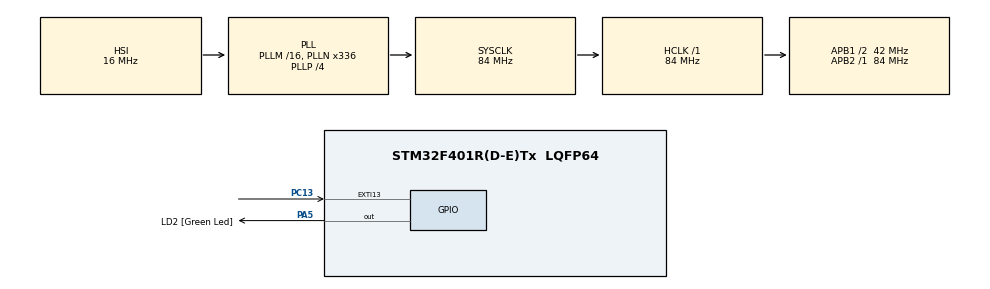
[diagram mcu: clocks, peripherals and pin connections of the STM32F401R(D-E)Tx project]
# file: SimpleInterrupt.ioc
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Mcu.Family=STM32F4
Mcu.Name=STM32F401R(D-E)Tx
Mcu.Package=LQFP64
NVIC.EXTI15_10_IRQn=true\:0\:1\:false\:false\:true
NVIC.PriorityGroup=NVIC_PRIORITYGROUP_0
PA13.GPIO_Label=TMS
PA13.Signal=SYS_JTMS-SWDIO
PA14.GPIO_Label=TCK
PA14.Signal=SYS_JTCK-SWCLK
PA2.GPIO_Label=USART_TX
PA2.GPIO_Mode=GPIO_MODE_AF_PP
PA2.GPIO_PuPd=GPIO_NOPULL
PA2.GPIO_Speed=GPIO_SPEED_FREQ_LOW
PA2.Signal=USART2_TX
PA3.GPIO_Label=USART_RX
PA3.GPIO_Mode=GPIO_MODE_AF_PP
PA3.GPIO_PuPd=GPIO_NOPULL
PA3.GPIO_Speed=GPIO_SPEED_FREQ_LOW
PA3.Signal=USART2_RX
PA5.GPIO_Label=LD2 [Green Led]
PA5.GPIO_Mode=GPIO_MODE_OUTPUT_PP
PA5.GPIO_PuPd=GPIO_NOPULL
PA5.GPIO_Speed=GPIO_SPEED_FREQ_LOW
PA5.Signal=GPIO_Output
PB3.GPIO_Label=SWO
PB3.Signal=SYS_JTDO-SWO
PC13-ANTI_TAMP.GPIO_ModeDefaultEXTI=GPIO_MODE_IT_FALLING
PC13-ANTI_TAMP.Signal=GPXTI13
PC14-OSC32_IN.Signal=RCC_OSC32_IN
PC15-OSC32_OUT.Signal=RCC_OSC32_OUT
PH0\ -\ OSC_IN.Signal=RCC_OSC_IN
PH1\ -\ OSC_OUT.Signal=RCC_OSC_OUT
ProjectManager.HeapSize=0x200
ProjectManager.StackSize=0x400
ProjectManager.TargetToolchain=SW4STM32
RCC.AHBFreq_Value=84000000
RCC.APB1CLKDivider=RCC_HCLK_DIV2
RCC.APB1Freq_Value=42000000
RCC.APB1TimFreq_Value=84000000
RCC.APB2Freq_Value=84000000
RCC.APB2TimFreq_Value=84000000
RCC.CortexFreq_Value=84000000
RCC.HCLKFreq_Value=84000000
RCC.HSE_VALUE=8000000
RCC.HSI_VALUE=16000000
RCC.LSE_VALUE=32768
RCC.PLLN=336
RCC.PLLP=RCC_PLLP_DIV4
RCC.PLLQ=7
RCC.SYSCLKFreq_VALUE=84000000
RCC.SYSCLKSource=RCC_SYSCLKSOURCE_PLLCLK
RCC.VCOOutputFreq_Value=336000000
board=NUCLEO-F401RE

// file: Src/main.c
/**
  ******************************************************************************
  * File Name          : main.c
  * Description        : Main program body
  ******************************************************************************
  *
  * COPYRIGHT(c) 2017 STMicroelectronics
  *
  * Redistribution and use in source and binary forms, with or without modification,
  * are permitted provided that the following conditions are met:
  *   1. Redistributions of source code must retain the above copyright notice,
  *      this list of conditions and the following disclaimer.
  *   2. Redistributions in binary form must reproduce the above copyright notice,
  *      this list of conditions and the following disclaimer in the documentation
  *      and/or other materials provided with the distribution.
  *   3. Neither the name of STMicroelectronics nor the names of its contributors
  *      may be used to endorse or promote products derived from this software
  *      without specific prior written permission.
  *
  * THIS SOFTWARE IS PROVIDED BY THE COPYRIGHT HOLDERS AND CONTRIBUTORS "AS IS"
  * AND ANY EXPRESS OR IMPLIED WARRANTIES, INCLUDING, BUT NOT LIMITED TO, THE
  * IMPLIED WARRANTIES OF MERCHANTABILITY AND FITNESS FOR A PARTICULAR PURPOSE ARE
  * DISCLAIMED. IN NO EVENT SHALL THE COPYRIGHT HOLDER OR CONTRIBUTORS BE LIABLE
  * FOR ANY DIRECT, INDIRECT, INCIDENTAL, SPECIAL, EXEMPLARY, OR CONSEQUENTIAL
  * DAMAGES (INCLUDING, BUT NOT LIMITED TO, PROCUREMENT OF SUBSTITUTE GOODS OR
  * SERVICES; LOSS OF USE, DATA, OR PROFITS; OR BUSINESS INTERRUPTION) HOWEVER
  * CAUSED AND ON ANY THEORY OF LIABILITY, WHETHER IN CONTRACT, STRICT LIABILITY,
  * OR TORT (INCLUDING NEGLIGENCE OR OTHERWISE) ARISING IN ANY WAY OUT OF THE USE
  * OF THIS SOFTWARE, EVEN IF ADVISED OF THE POSSIBILITY OF SUCH DAMAGE.
  *
  ******************************************************************************
  */
#include "main.h"
#include "stm32f4xx_hal.h"
#include "gpio.h"

/* USER CODE BEGIN PV */
/* Private variables ---------------------------------------------------------*/

/* USER CODE END PV */

void SystemClock_Config(void);
void Error_Handler(void);

/* USER CODE BEGIN PFP */
/* Private function prototypes -----------------------------------------------*/

/* USER CODE END PFP */

int main(void)
{

  /* MCU Configuration----------------------------------------------------------*/

  /* Reset of all peripherals, Initializes the Flash interface and the Systick. */
  HAL_Init();

  /* Configure the system clock */
  SystemClock_Config();

  /* Initialize all configured peripherals */
  MX_GPIO_Init();

  /* Infinite loop */
  while (1)
  {

  }

}

/** System Clock Configuration
*/
void SystemClock_Config(void)
{

  RCC_OscInitTypeDef RCC_OscInitStruct;
  RCC_ClkInitTypeDef RCC_ClkInitStruct;

    /**Configure the main internal regulator output voltage
    */
  __HAL_RCC_PWR_CLK_ENABLE();

  __HAL_PWR_VOLTAGESCALING_CONFIG(PWR_REGULATOR_VOLTAGE_SCALE2);

    /**Initializes the CPU, AHB and APB busses clocks
    */
  RCC_OscInitStruct.OscillatorType = RCC_OSCILLATORTYPE_HSI;
  RCC_OscInitStruct.HSIState = RCC_HSI_ON;
  RCC_OscInitStruct.HSICalibrationValue = 16;
  RCC_OscInitStruct.PLL.PLLState = RCC_PLL_ON;
  RCC_OscInitStruct.PLL.PLLSource = RCC_PLLSOURCE_HSI;
  RCC_OscInitStruct.PLL.PLLM = 16;
  RCC_OscInitStruct.PLL.PLLN = 336;
  RCC_OscInitStruct.PLL.PLLP = RCC_PLLP_DIV4;
  RCC_OscInitStruct.PLL.PLLQ = 7;
  if (HAL_RCC_OscConfig(&RCC_OscInitStruct) != HAL_OK)
  {
    Error_Handler();
  }

    /**Initializes the CPU, AHB and APB busses clocks
    */
  RCC_ClkInitStruct.ClockType = RCC_CLOCKTYPE_HCLK|RCC_CLOCKTYPE_SYSCLK
                              |RCC_CLOCKTYPE_PCLK1|RCC_CLOCKTYPE_PCLK2;
  RCC_ClkInitStruct.SYSCLKSource = RCC_SYSCLKSOURCE_PLLCLK;
  RCC_ClkInitStruct.AHBCLKDivider = RCC_SYSCLK_DIV1;
  RCC_ClkInitStruct.APB1CLKDivider = RCC_HCLK_DIV2;
  RCC_ClkInitStruct.APB2CLKDivider = RCC_HCLK_DIV1;

  if (HAL_RCC_ClockConfig(&RCC_ClkInitStruct, FLASH_LATENCY_2) != HAL_OK)
  {
    Error_Handler();
  }

    /**Configure the Systick interrupt time
    */
  HAL_SYSTICK_Config(HAL_RCC_GetHCLKFreq()/1000);

    /**Configure the Systick
    */
  HAL_SYSTICK_CLKSourceConfig(SYSTICK_CLKSOURCE_HCLK);

  /* SysTick_IRQn interrupt configuration */
  HAL_NVIC_SetPriority(SysTick_IRQn, 0, 0);
}

/* USER CODE BEGIN 4 */
void HAL_GPIO_EXTI_Callback(uint16_t GPIO_Pin) {
	__disable_irq();
    GPIO_PinState state = HAL_GPIO_ReadPin(LD2_GPIO_Port, LD2_Pin);
    if (state == GPIO_PIN_SET) {
      HAL_GPIO_WritePin(LD2_GPIO_Port, LD2_Pin, GPIO_PIN_RESET);
    } else {
      HAL_GPIO_WritePin(LD2_GPIO_Port, LD2_Pin, GPIO_PIN_SET);
    }
    __enable_irq();
}
/* USER CODE END 4 */

void Error_Handler(void)
{
  while(1)
  {
  }
}

/************************ (C) COPYRIGHT STMicroelectronics *****END OF FILE****/
